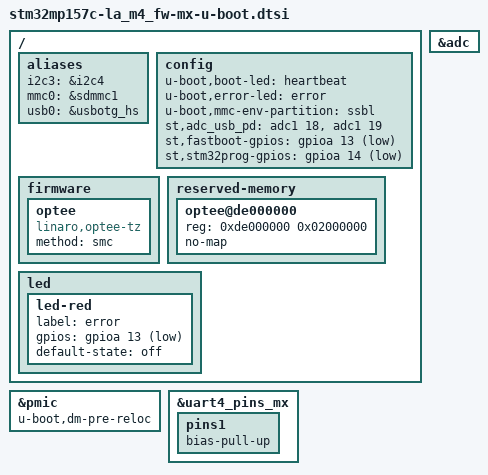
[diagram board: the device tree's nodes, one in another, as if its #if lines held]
// SPDX-License-Identifier: (GPL-2.0-or-later OR BSD-3-Clause)
/*
 * Copyright (C) 2023, STMicroelectronics - All Rights Reserved
 * Author: STM32CubeMX code generation for STMicroelectronics.
 */

/* For more information on Device Tree configuration, please refer to
 * https://wiki.st.com/stm32mpu/wiki/Category:Device_tree_configuration
 */

/* USER CODE BEGIN includes */
/* USER CODE END includes */

/ {

	/* USER CODE BEGIN root */

	aliases{
		i2c3 = &i2c4;
		mmc0 = &sdmmc1;
		usb0 = &usbotg_hs;
	};

	config{
		u-boot,boot-led = "heartbeat";
		u-boot,error-led = "error";
		u-boot,mmc-env-partition = "fip";
		st,adc_usb_pd = <&adc1 18>, <&adc1 19>;
		st,fastboot-gpios = <&gpioa 13 GPIO_ACTIVE_LOW>;
		st,stm32prog-gpios = <&gpioa 14 GPIO_ACTIVE_LOW>;
	};

#ifdef CONFIG_STM32MP15x_STM32IMAGE

	config{
		u-boot,mmc-env-partition = "ssbl";
	};

	firmware{

		optee{
			compatible = "linaro,optee-tz";
			method = "smc";
		};
	};

	reserved-memory{

		optee@de000000{
			reg = <0xde000000 0x02000000>;
			no-map;
		};
	};
#endif

	led{

		led-red{
			label = "error";
			gpios = <&gpioa 13 GPIO_ACTIVE_LOW>;
			default-state = "off";
			status = "okay";
		};
	};
	/* USER CODE END root */

}; /*root*/

/* USER CODE BEGIN addons */
#ifndef CONFIG_TFABOOT

&pmic{
	u-boot,dm-pre-reloc;
};

#endif /*CONFIG_TFABOOT*/

&uart4_pins_mx {
	pins1 {	/* UART4_RX */
		/* pull-up on rx to avoid floating level */
		bias-pull-up;
	};
};


&adc{
	status = "okay";
};

/* USER CODE END addons */

